# LPC55S16 register map
Vendor: nxp.com; File version: 1.0
CPU: CM33 r2p0, little endian, MPU, FPU, VTOR, 3 interrupt priority bits
Registers are 32-bit, read-write, reset 0x0 unless marked. A register's access mark holds for its fields unless they carry their own. Offsets are from the block's base; [hi:lo] are bit positions; lines under a group give offsets from that group; {n}, {i} and the like mark numbered series.

## FLASH_KEY_STORE
Base 0x0003E600
0x00 HEADER — Valid Key Sore Header : 0x95959595
  [31:0] FIELD
0x04 puf_discharge_time_in_ms
  [31:0] FIELD
{0x8+4i} ACTIVATION_CODE[{i}] (i=0..297)
  [31:0] FIELD
0x4B0 SBKEY_HEADER0 (SBKEY_KEY_CODE view)
  [31:0] FIELD
{0x4B0+4i} SBKEY_KEY_CODE{i} (SBKEY_KEY_CODE view) (i=0..13)
  [31:0] FIELD
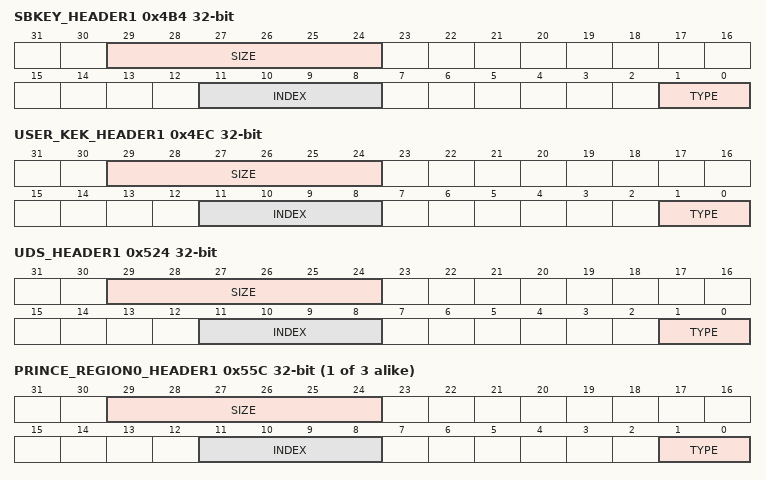
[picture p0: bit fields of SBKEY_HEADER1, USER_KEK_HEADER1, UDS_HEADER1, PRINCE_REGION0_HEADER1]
0x4B4 SBKEY_HEADER1 (SBKEY_KEY_CODE view)
  [29:24] SIZE, [11:8] INDEX, [1:0] TYPE
{0x4B8+4i} SBKEY_BODY{i} (SBKEY_KEY_CODE view) (i=0..11)
  [31:0] FIELD
0x4E8 USER_KEK_HEADER0 (USER_KEK_KEY_CODE view)
  [31:0] FIELD
{0x4E8+4i} USER_KEK_KEY_CODE{i} (USER_KEK_KEY_CODE view) (i=0..13)
  [31:0] FIELD
0x4EC USER_KEK_HEADER1 (USER_KEK_KEY_CODE view)
  [29:24] SIZE, [11:8] INDEX, [1:0] TYPE
{0x4F0+4i} USER_KEK_BODY{i} (USER_KEK_KEY_CODE view) (i=0..11)
  [31:0] FIELD
0x520 UDS_HEADER0 (UDS_KEY_CODE view)
  [31:0] FIELD
{0x520+4i} UDS_KEY_CODE{i} (UDS_KEY_CODE view) (i=0..13)
  [31:0] FIELD
0x524 UDS_HEADER1 (UDS_KEY_CODE view)
  [29:24] SIZE, [11:8] INDEX, [1:0] TYPE
{0x528+4i} UDS_BODY{i} (UDS_KEY_CODE view) (i=0..11)
  [31:0] FIELD
{0x558+0x38*i} PRINCE_REGION{i}_HEADER0 (PRINCE_REGION{i}_KEY_CODE view) (i=0..2)
  [31:0] FIELD
{0x558+4i} PRINCE_REGION0_KEY_CODE{i} (PRINCE_REGION0_KEY_CODE view) (i=0..13)
  [31:0] FIELD
{0x55C+0x38*i} PRINCE_REGION{i}_HEADER1 (PRINCE_REGION{i}_KEY_CODE view) (i=0..2)
  [29:24] SIZE, [11:8] INDEX, [1:0] TYPE
{0x560+4i} PRINCE_REGION0_BODY{i} (PRINCE_REGION0_KEY_CODE view) (i=0..11)
  [31:0] FIELD
{0x590+4i} PRINCE_REGION1_KEY_CODE{i} (PRINCE_REGION1_KEY_CODE view) (i=0..13)
  [31:0] FIELD
{0x598+4i} PRINCE_REGION1_BODY{i} (PRINCE_REGION1_KEY_CODE view) (i=0..11)
  [31:0] FIELD
{0x5C8+4i} PRINCE_REGION2_KEY_CODE{i} (PRINCE_REGION2_KEY_CODE view) (i=0..13)
  [31:0] FIELD
{0x5D0+4i} PRINCE_REGION2_BODY{i} (PRINCE_REGION2_KEY_CODE view) (i=0..11)
  [31:0] FIELD

## FLASH_ROMPATCH
Base 0x0003EC00
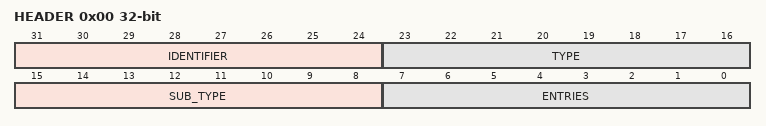
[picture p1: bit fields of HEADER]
0x00 HEADER
  [31:24] IDENTIFIER, [23:16] TYPE, [15:8] SUB_TYPE, [7:0] ENTRIES
{0x4+4i} PATCH[{i}] (i=0..254)
  [31:0] PATCH

## GINT0 — Group GPIO input interrupt (GINT0/1)
Base 0x40002000
Same registers: GINT1 0x40003000
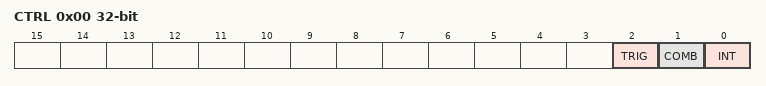
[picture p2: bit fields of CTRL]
0x00 CTRL — GPIO grouped interrupt control register
  [2] TRIG — Group interrupt trigger
    0=EDGE_TRIGGERED; 1=LEVEL_TRIGGERED
  [1] COMB — Combine enabled inputs for group interrupt
    0=OR (Or. OR functionality: A grouped interrupt is generated when any one of the enabled inputs is active (based on its programmed polarity).); 1=AND (And. AND functionality: An interrupt is generated when all enabled bits are active (based on their programmed polarity).)
  [0] INT — Group interrupt status. This bit is cleared by writing a one to it. Writing zero has no effect.
    0=NO_REQUEST (No request. No interrupt request is pending.); 1=REQUEST_ACTIVE (Request active. Interrupt request is active.)
{0x20+4i} PORT_POL[{i}] (i=0..1) reset 0xFFFFFFFF — GPIO grouped interrupt port 0 polarity register
  [31:0] POL — Configure pin polarity of port m pins for group interrupt. Bit n corresponds to pin PIOm_n of port m. 0 = the pin is active LOW. If the level on this pin is LOW, the pin contributes to the group interrupt. 1 = the pin is active HIGH. If the level on this pin is HIGH, the pin contributes to the group interrupt.
{0x40+4i} PORT_ENA[{i}] (i=0..1) — GPIO grouped interrupt port 0 enable register
  [31:0] ENA — Enable port 0 pin for group interrupt. Bit n corresponds to pin Pm_n of port m. 0 = the port 0 pin is disabled and does not contribute to the grouped interrupt. 1 = the port 0 pin is enabled and contributes to the grouped interrupt.

## WWDT — Windowed Watchdog Timer (WWDT)
Base 0x4000C000
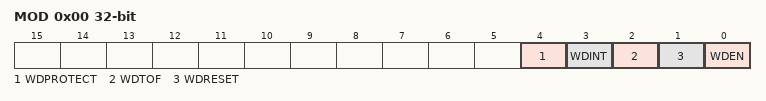
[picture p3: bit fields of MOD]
0x00 MOD — Watchdog mode register. This register contains the basic mode and status of the Watchdog Timer.
  [4] WDPROTECT — Watchdog update mode. This bit can be set once by software and is only cleared by a reset.
    0=FLEXIBLE (Flexible. The watchdog time-out value (TC) can be changed at any time.); 1=THRESHOLD (Threshold. The watchdog time-out value (TC) can be changed only after the counter is below the value of WDWARNINT and WDWINDOW.)
  [3] WDINT — Warning interrupt flag. Set when the timer is at or below the value in WDWARNINT. Cleared by software writing a 1 to this bit position. Note that this bit cannot be cleared while the WARNINT value is equal to the value of the TV register. This can occur if the value of WARNINT is 0 and the WDRESET bit is 0 when TV decrements to 0.
  [2] WDTOF — Watchdog time-out flag. Set when the watchdog timer times out, by a feed error, or by events associated with WDPROTECT. Cleared by software writing a 0 to this bit position. Causes a chip reset if WDRESET = 1.
  [1] WDRESET — Watchdog reset enable bit. Once this bit has been written with a 1 it cannot be re-written with a 0.
    0=INTERRUPT (Interrupt. A watchdog time-out will not cause a chip reset.); 1=RESET (Reset. A watchdog time-out will cause a chip reset.)
  [0] WDEN — Watchdog enable bit. Once this bit is set to one and a watchdog feed is performed, the watchdog timer will run permanently.
    0=STOP (Stop. The watchdog timer is stopped.); 1=RUN (Run. The watchdog timer is running.)
0x04 TC reset 0xFF — Watchdog timer constant register. This 24-bit register determines the time-out value.
  [23:0] COUNT — Watchdog time-out value.
0x08 FEED wo reset not defined — Watchdog feed sequence register. Writing 0xAA followed by 0x55 to this register reloads the Watchdog timer with the value contained in TC.
  [7:0] FEED — Feed value should be 0xAA followed by 0x55.
0x0C TV ro reset 0xFF — Watchdog timer value register. This 24-bit register reads out the current value of the Watchdog timer.
  [23:0] COUNT — Counter timer value.
0x14 WARNINT — Watchdog Warning Interrupt compare value.
  [9:0] WARNINT — Watchdog warning interrupt compare value.
0x18 WINDOW reset 0xFFFFFF — Watchdog Window compare value.
  [23:0] WINDOW — Watchdog window value.
